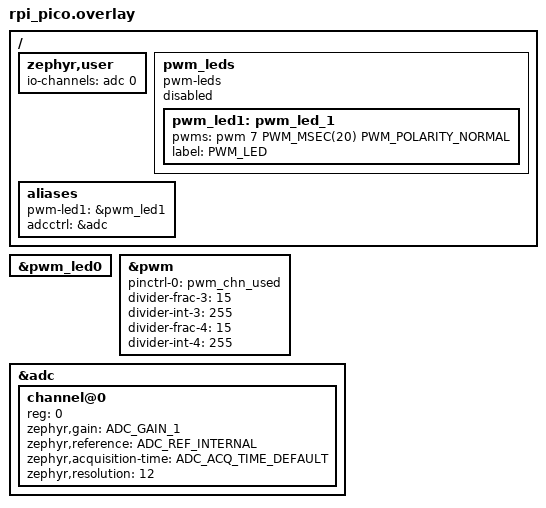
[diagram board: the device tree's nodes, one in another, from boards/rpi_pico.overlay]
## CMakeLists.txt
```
# SPDX-License-Identifier: Apache-2.0

cmake_minimum_required(VERSION 3.20.0)

find_package(Zephyr REQUIRED HINTS $ENV{ZEPHYR_BASE})
project(ADC)

target_sources(app PRIVATE src/main.c)
```

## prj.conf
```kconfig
CONFIG_ADC=y



CONFIG_STDOUT_CONSOLE=y
CONFIG_PRINTK=y
CONFIG_PWM=y
CONFIG_LOG=y
CONFIG_LOG_PRINTK=y
CONFIG_LOG_MODE_IMMEDIATE=y
CONFIG_PWM_LOG_LEVEL_DBG=y
```

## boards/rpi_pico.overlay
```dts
#include <zephyr/dt-bindings/adc/adc.h>
#include "rpi_pico-pinctrl.dtsi"

/ {
	zephyr,user {
		io-channels = <&adc 0>;
	};
	
	pwm_leds {
		compatible = "pwm-leds";
		status = "disabled";
		pwm_led1: pwm_led_1 {
			pwms = <&pwm 7 PWM_MSEC(20) PWM_POLARITY_NORMAL>;
			label = "PWM_LED";
		};
	};

	aliases {
		pwm-led1 = &pwm_led1;
		adcctrl = &adc;
	};
};


&pwm_led0 {
	status = "okay";
};

&pwm {
	status = "okay";

	pinctrl-0 = <&pwm_chn_used>;

	// for pwm chanel 3 A and B

	divider-frac-3 = <15>;
	divider-int-3 = <255>;
	
	// for pwm chanel 4 A and B
	
	divider-frac-4 = <15>;
	divider-int-4 = <255>;
};

&adc {
	status = "okay";
	#address-cells = <1>;
	#size-cells = <0>;

	channel@0 {
		reg = <0>;
		zephyr,gain = "ADC_GAIN_1";
		zephyr,reference = "ADC_REF_INTERNAL";
		zephyr,acquisition-time = <ADC_ACQ_TIME_DEFAULT>;
		zephyr,resolution = <12>;
	};
};
```

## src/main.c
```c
/*
 * Copyright (c) 2020 Libre Solar Technologies GmbH
 *
 * SPDX-License-Identifier: Apache-2.0
 */

 //############## ADC #######################

#include <inttypes.h>
#include <stddef.h>
#include <stdint.h>

#include <zephyr/device.h>
#include <zephyr/devicetree.h>
#include <zephyr/drivers/adc.h>
#include <zephyr/kernel.h>
#include <zephyr/sys/printk.h>
#include <zephyr/sys/util.h>

#if !DT_NODE_EXISTS(DT_PATH(zephyr_user)) || \
	!DT_NODE_HAS_PROP(DT_PATH(zephyr_user), io_channels)
#error "No suitable devicetree overlay specified"
#endif

#define DT_SPEC_AND_COMMA(node_id, prop, idx) \
	ADC_DT_SPEC_GET_BY_IDX(node_id, idx),

/* Data of ADC io-channels specified in devicetree. */
static const struct adc_dt_spec adc_channels[] = {
	DT_FOREACH_PROP_ELEM(DT_PATH(zephyr_user), io_channels,
			     DT_SPEC_AND_COMMA)
};


 //############## PWM #######################

#include <zephyr/kernel.h>
#include <zephyr/sys/printk.h>
#include <zephyr/device.h>
#include <zephyr/drivers/pwm.h>

static const struct pwm_dt_spec pwm_led0 = PWM_DT_SPEC_GET(DT_ALIAS(pwm_led0));
static const struct pwm_dt_spec pwm_led1 = PWM_DT_SPEC_GET(DT_ALIAS(pwm_led1));

#define MIN_PERIOD PWM_SEC(1U) / 128U
#define MAX_PERIOD PWM_SEC(1U)



 //!!!!!!!!!!############## MAIN #######################!!!!!!!!

void main(void)
{
	 //############## MAIN ADC #######################
	int err;
	uint16_t buf;
	struct adc_sequence sequence = {
		.buffer = &buf,
		/* buffer size in bytes, not number of samples */
		.buffer_size = sizeof(buf),
	};

	/* Configure channels individually prior to sampling. */
	for (size_t i = 0U; i < ARRAY_SIZE(adc_channels); i++) {
		if (!device_is_ready(adc_channels[i].dev)) {
			printk("ADC controller device not ready\n");
			return;
		}

		err = adc_channel_setup_dt(&adc_channels[i]);
		if (err < 0) {
			printk("Could not setup channel #%d (%d)\n", i, err);
			return;
		}
	}

	 //############## MAIN PWM #######################
	uint32_t min_period;
	uint32_t max_period;
	uint32_t period;
	int ret;
	uint32_t duty_cycle;

	printk("PWM-based blinky\n");

	if (!device_is_ready(pwm_led0.dev)) {
		printk("Error: PWM device %s is not ready\n",
		       pwm_led0.dev->name);
		return;
	}

	if (!device_is_ready(pwm_led1.dev)) {
		printk("Error: PWM device %s is not ready\n",
		       pwm_led1.dev->name);
		return;
	}

	/*
	 * In case the default MAX_PERIOD value cannot be set for
	 * some PWM hardware, decrease its value until it can.
	 *
	 * Keep its value at least MIN_PERIOD * 4 to make sure
	 * the sample changes frequency at least once.
	 */
	printk("Calibrating for channel %d...\n", pwm_led0.channel);
	max_period = MAX_PERIOD;
	while (pwm_set_dt(&pwm_led0, max_period, max_period / 2U)) {
		max_period /= 2U;
		if (max_period < (4U * MIN_PERIOD)) {
			printk("Error: PWM device "
			       "does not support a period at least %lu\n",
			       4U * MIN_PERIOD);
			return;
		}
	}


	printk("Done calibrating; maximum/minimum periods %u/%lu nsec\n",
	       max_period, MIN_PERIOD);

	period = max_period;





	while (1) {

		//############# INIT ADC ####################
		printk("ADC reading:\n");
		for (size_t i = 0U; i < ARRAY_SIZE(adc_channels); i++) {
			int32_t val_mv;

			printk("- %s, channel %d: ",
			       adc_channels[i].dev->name,
			       adc_channels[i].channel_id);

			(void)adc_sequence_init_dt(&adc_channels[i], &sequence);


			err = adc_read(adc_channels[i].dev, &sequence);
			if (err < 0) {
				printk("Could not read (%d)\n", err);
				continue;
			} else {
				printk("%"PRIu16, buf);
			}

			/* conversion to mV may not be supported, skip if not */
			val_mv = buf;
			err = adc_raw_to_millivolts_dt(&adc_channels[i],
						       &val_mv);
			if (err < 0) {
				printk(" (value in mV not available)\n");
			} else {
				printk(" = %"PRId32" mV\n", val_mv);
			}


			//################# CHANGE PWM ######################
			if(i==0){
			duty_cycle = buf/sizeof(buf)*period;
			//period = (adc_read(adc_channels[0].dev, &sequence)/sizeof(buf))*PWM_MSEC(1000U);
			ret = pwm_set_dt(&pwm_led0, period, duty_cycle);
			if (ret) {
				printk("Error %d: failed to set pulse width\n", ret);
				return;
			}

			//ret = pwm_set_dt(&pwm_led1, period, duty_cycle);
			//if (ret) {
			//	printk("Error %d: failed to set pulse width\n", ret);
			//	return;
			//}

			k_sleep(K_SECONDS(4U));
		}

		}

		k_sleep(K_MSEC(1000));
	}
}
```
